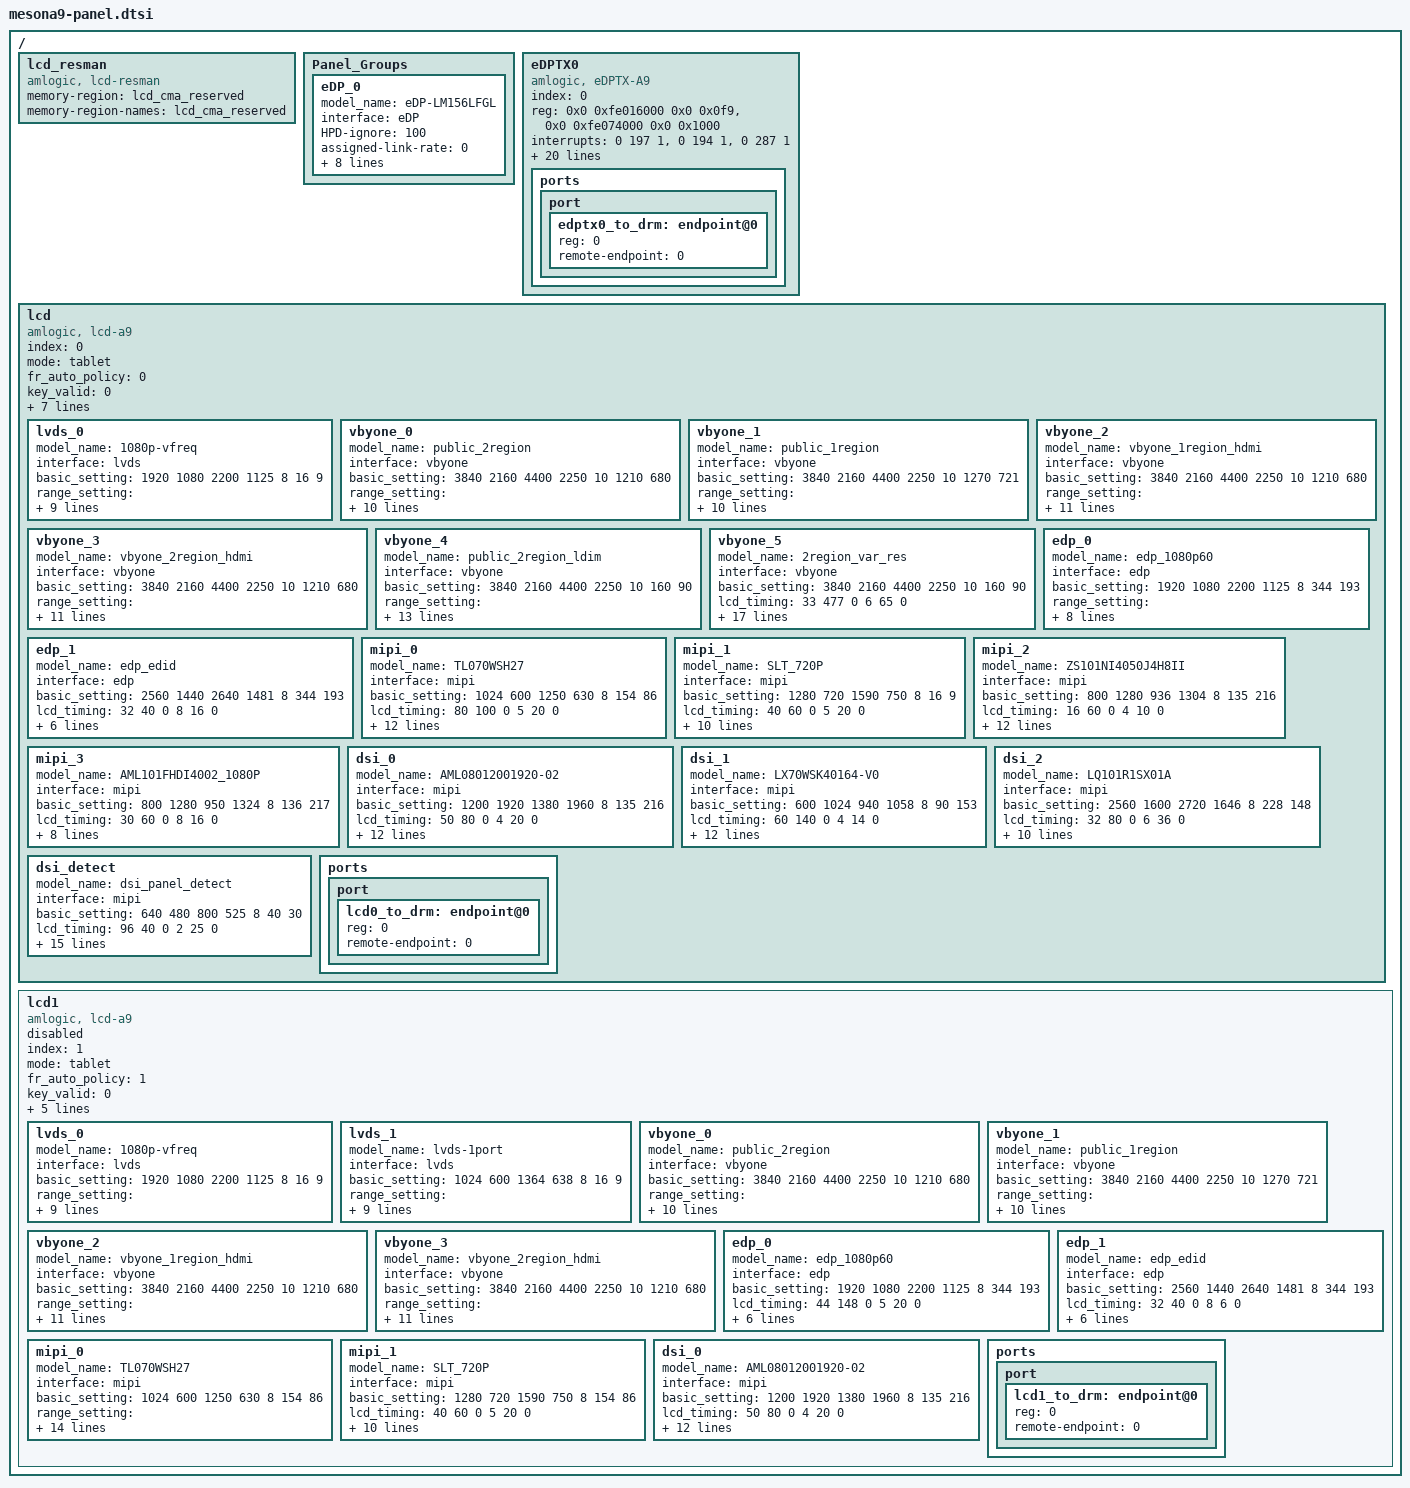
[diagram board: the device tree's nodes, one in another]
// SPDX-License-Identifier: (GPL-2.0+ OR MIT)
/*
 * Copyright (c) 2019 Amlogic, Inc. All rights reserved.
 */

/ {
	lcd_resman {
		compatible = "amlogic, lcd-resman";
		status = "okay";
		memory-region = <&lcd_cma_reserved>;
		memory-region-names = "lcd_cma_reserved";
	};

	Panel_Groups {
		eDP_0 {
			model_name = "eDP-LM156LFGL";
			interface = "eDP"; /*lcd_interface(lvds, vbyone)*/
			HPD-ignore = <100>;

			assigned-link-rate = <0>;
			assigned-lane-count = <0>;
			assigned-port-count = <0>;
			assigned-vmode = <0>;
			assigned-disable-PSR = <0>;
			use-aux-backlight = <0>;

			assigned-preset-timing = <0>;

			///*h(period active sync bp pol) v(period active sync bp pol) dft fr*/
			//timing-0 = <2180 1920 32 180 0 1282 1080 5 194 0 24 48>;
			//timing-0-fr = <48 50 60>; /* timing with fixed fr */
			//timing-0-range-limit = <
			//	2132 2650  /*h_period_min,max*/
			//	1120 1480  /*v_period_min,max*/
			//	120000000 160000000>; /*pclk_min,max*/
			//timing-0-range = <48 60>; /* timing with fixed fr */

			phy_attr=<1 2 0>; /*Fast-LT vswing, Pre-Em, Post-Cur*/
			bl-wrapper-id = <0xff000000>;
		};
	};

	eDPTX0:eDPTX0 {
		compatible = "amlogic, eDPTX-A9";
		status = "okay";
		index = <0>;

		reg = <0x0 0xfe016000 0x0 0x0f9>,    /* combo dphy */
		      <0x0 0xfe074000 0x0 0x1000>;  /* edp_a host */
		//power-domains = <&pwrdm PDID_T7_EDP0>;
		interrupts = <0 197 1>,<0 194 1>,<0 287 1>;
		interrupt-names = "vsync","vsync2","eDPTX-HPD";
		pinctrl-names = "edptx_hpd","edptx_hpd_off";
		pinctrl-0 = <&edptx_0_hpd_pins>;
		pinctrl-1 = <&edptx_0_hpd_off_pins>;
		device_name = "amlogic-eDPTX0";

		HPD-ignore = <100>;

		//edptx_vcc-gpio      = <&gpio GPIOY_0 GPIO_ACTIVE_HIGH>;
		//edptx_vcc-gpio-name = "GPIOY_0";
		//edptx_vcc_on_dir = <1>;
		//edptx_vcc-off_dir = <0>;

		edptx_bl_en-gpio      = <&gpio GPIOY_0 GPIO_ACTIVE_HIGH>;
		edptx_bl_en-gpio-name = "GPIOY_0";
		edptx_bl_en_on_dir = <1>;
		edptx_bl_en-off_dir = <0>;
		edptx_bl_pwm-gpio      = <&gpio GPIOY_1 GPIO_ACTIVE_HIGH>;
		edptx_bl_pwm-gpio-name = "GPIOY_1";
		edptx_bl_pwm_on_dir = <1>;
		edptx_bl_pwm-off_dir = <0>;

		edptx_bist-gpio      = <&gpio GPIOY_3 GPIO_ACTIVE_HIGH>;
		edptx_bist-gpio-name = "GPIOY_3";
		edptx_bist_on_dir = <1>;
		edptx_bist-off_dir = <0>;

		//edptx_hpd-gpio      = <&gpio GPIOY_7 GPIO_ACTIVE_HIGH>;
		//edptx_hpd-gpio-name = "GPIOY_7";

		drive-strength-lut =
			<0x3 0x3 0x0>,<0x3 0x7 0x0>,<0x3 0xb 0x0>,<0x3 0xf 0x0>,
			<0x7 0x3 0x0>,<0x7 0x8 0x0>,<0x8 0xc 0x0>,
			<0xa 0x4 0x0>,<0xa 0x8 0x0>,
			<0xf 0x5 0x0>;

		ports {
			port {
				#address-cells = <1>;
				#size-cells = <0>;
				edptx0_to_drm: endpoint@0 {
					reg = <0>;
					remote-endpoint = <0>;
				};
			};
		};
	};

	lcd:lcd {
		compatible = "amlogic, lcd-a9";
		status = "okay";
		index = <0>;
		mode = "tablet";
		fr_auto_policy = <0>; /* 0=disable, 1=60/50hz, 2=60/50/48hz */
		key_valid = <0>;
		reg = <0x0 0xfe01e000 0x0 0x400   /* mipi_dsi0-A host */
			0x0 0xfe01c000 0x0 0x200   /* mipi_dsi0-A phy */
			0x0 0xfe072000 0x0 0x400   /* mipi_dsi0-B host */
			0x0 0xfe018000 0x0 0x200   /* mipi_dsi0-B phy */
			0x0 0xfe016000 0x0 0x3e4
			0x0 0xfe004000 0x0 0x070>;  /* vx1_lvds_ctrl */
		interrupts = <0 197 1>, <0 194 1>, <0 208 1>;
		interrupt-names = "vsync","vsync2","vbyone";
		pinctrl-names = "vbyone","vbyone_off";
		pinctrl-0 = <&lcd_vbyone_a_pins>;
		pinctrl-1 = <&lcd_vbyone_a_off_pins>;

		config_check_glb = <1>;
		display_timing_req_min = <1  /*alert_level: 0:disable, 1:warning, 2:fatal error*/
			45   /*hsw+hbp*/
			0    /*hfp, 0 for no need*/
			20   /*vsw+vbp*/
			15>; /*vfp*/
		lvds_0{
			model_name = "1080p-vfreq";
			interface = "lvds"; /*lcd_interface(lvds, vbyone)*/
			basic_setting = <
				1920 1080 /*h_active, v_active*/
				2200 1125 /*h_period, v_period*/
				8      /*lcd_bits */
				16 9>; /*screen_widht, screen_height*/
			range_setting = <
				2132 2650  /*h_period_min,max*/
				1120 1480  /*v_period_min,max*/
				120000000 160000000>; /*pclk_min,max*/
			lcd_timing = <
				44 148 0  /*hs_width, hs_bp, hs_pol*/
				5  20 0>; /*vs_width, vs_bp, vs_pol*/
			clk_attr = <
				2 /*fr_adj_type: 0=clk, 1=htotal, 2=vtotal, 3=auto, 4=hdmi */
				0 /*clk_ss: [0:7]:level, [8:11]:freq, [12:15]: mode*/
				1 /*clk_auto_generate*/
				0>; /*pixel_clk(unit in Hz)*/
			lvds_attr = <
				1  /*lvds_repack*/
				1  /*dual_port*/
				0  /*pn_swap*/
				0  /*port_swap*/
				0>; /*lane_reverse*/
			phy_attr=<0x3 0>; /*vswing_level, preem_level*/
			hw_filter=<0 0>;  /* filter_time, filter_cnt*/

			/* power step: type, index, value, delay(ms) */
			power_on_step = <
				2 0 0 0   /*signal enable*/
				0xff 0 0 0>; /*ending*/
			power_off_step = <
				2 0 0 10  /*signal disable*/
				0xff 0 0 0>; /*ending*/
			backlight_index = <0xff>;
		};
		vbyone_0{
			model_name = "public_2region";
			interface = "vbyone"; /*lcd_interface(lvds, vbyone)*/
			basic_setting = <
				3840 2160 /*h_active, v_active*/
				4400 2250 /*h_period, v_period*/
				10     /*lcd_bits */
				1210 680>; /*screen_widht, screen_height*/
			range_setting = <
				4370 4800 /*h_period_min, max*/
				2246 2760 /*v_period_min, max*/
				480000000 624000000>; /*pclk_min, max*/
			lcd_timing = <
				33 477 0  /*hs_width, hs_bp, hs_pol*/
				6  65 0>; /*vs_width, vs_bp, vs_pol*/
			clk_attr = <
				2 /*fr_adj_type: 0=clk, 1=htotal, 2=vtotal, 3=auto, 4=hdmi */
				0 /*clk_ss: [0:7]:level, [8:11]:freq, [12:15]: mode*/
				1 /*clk_auto_generate*/
				0>; /*pixel_clk(unit in Hz)*/
			vbyone_attr = <
				8 /*lane_count*/
				2 /*region_num*/
				4 /*byte_mode*/
				4>; /*color_fmt*/
			vbyone_intr_enable = <
				1 /*vbyone_intr_enable */
				3>; /*vbyone_vsync_intr_enable*/
			phy_attr=<0x8 0xf>; /* vswing_level, preem_level */
			hw_filter=<0 0>;  /* filter_time, filter_cnt*/

			/* power step: type, index, value, delay(ms) */
			power_on_step = <
				0 0 1 200  /*panel power on*/
				2 0 0 10  /*signal enable*/
				0xff 0 0 0>; /*ending*/
			power_off_step = <
				2 0 0 10 /*signal disable*/
				0 0 0 500 /*panel power off*/
				0xff 0 0 0>; /*ending*/
			backlight_index = <0>;
		};
		vbyone_1{
			model_name = "public_1region";
			interface = "vbyone"; /*lcd_interface(lvds, vbyone)*/
			basic_setting = <
				3840 2160 /*h_active, v_active*/
				4400 2250 /*h_period, v_period*/
				10     /*lcd_bits*/
				1270 721>; /*screen_widht, screen_height*/
			range_setting = <
				4370 4800 /*h_period_min, max*/
				2246 2790 /*v_period_min, max*/
				552000000 632000000>; /*pclk_min,max*/
			lcd_timing = <
				33 477 0   /*hs_width, hs_bp, hs_pol*/
				6  65  0>; /*vs_width, vs_bp, vs_pol*/
			clk_attr = <
				2 /*fr_adj_type: 0=clk, 1=htotal, 2=vtotal, 3=auto, 4=hdmi */
				0 /*clk_ss: [0:7]:level, [8:11]:freq, [12:15]: mode*/
				1 /*clk_auto_generate*/
				0>; /*pixel_clk(unit in Hz)*/
			vbyone_attr = <
				8 /*lane_count*/
				1 /*region_num*/
				4 /*byte_mode*/
				4>; /*color_fmt*/
			vbyone_intr_enable = <
				1   /*vbyone_intr_enable*/
				3>; /*vbyone_vsync_intr_enable*/
			phy_attr=<0x8 0xf>; /* vswing_level, preem_level */
			hw_filter=<0 0>;  /* filter_time, filter_cnt*/

			/* power step: type, index, value, delay(ms) */
			power_on_step = <
				0 0 1 200  /*panel power on*/
				2 0 0 10 /*signal enable*/
				0xff 0 0 0>; /*ending*/
			power_off_step = <
				2 0 0 10  /*signal disable*/
				0 0 0 500 /*panel power off*/
				0xff 0 0 0>; /*ending*/
			backlight_index = <0>;
		};
		vbyone_2{
			model_name = "vbyone_1region_hdmi";
			interface = "vbyone"; /*lcd_interface(lvds, vbyone)*/
			basic_setting = <
				3840 2160 /*h_active, v_active*/
				4400 2250 /*h_period, v_period*/
				10     /*lcd_bits */
				1210 680>; /*screen_widht, screen_height*/
			range_setting = <
				4370 4800 /*h_period_min, max*/
				2246 2760 /*v_period_min, max*/
				480000000 624000000>; /*pclk_min, max*/
			lcd_timing = <
				33 477 0  /*hs_width, hs_bp, hs_pol*/
				6  65 0>; /*vs_width, vs_bp, vs_pol*/
			clk_attr = <
				4 /*fr_adj_type: 0=clk, 1=htotal, 2=vtotal, 3=auto, 4=hdmi */
				0 /*clk_ss: [0:7]:level, [8:11]:freq, [12:15]: mode*/
				1 /*clk_auto_generate*/
				0>; /*pixel_clk(unit in Hz)*/
			vbyone_attr = <
				8 /*lane_count*/
				1 /*region_num*/
				4 /*byte_mode*/
				4>; /*color_fmt*/
			vbyone_intr_enable = <
				1 /*vbyone_intr_enable */
				3>; /*vbyone_vsync_intr_enable*/
			phy_attr=<0x8 0xf>; /* vswing_level, preem_level */
			hw_filter=<0 0>;  /* filter_time, filter_cnt*/
			//vlock_attr: <vlock_en vlock_mode pll_m limit line_limit>
			vlock_attr = <0 4 0 3>;
			/* power step: type, index, value, delay(ms) */
			power_on_step = <
				0 0 1 20  /*panel power on*/
				2 0 0 0  /*signal enable*/
				0xff 0 0 0>; /*ending*/
			power_off_step = <
				2 0 0 20 /*signal disable*/
				0 0 0 100 /*panel power off*/
				0xff 0 0 0>; /*ending*/
			backlight_index = <0xff>;
		};
		vbyone_3{
			model_name = "vbyone_2region_hdmi";
			interface = "vbyone"; /*lcd_interface(lvds, vbyone)*/
			basic_setting = <
				3840 2160 /*h_active, v_active*/
				4400 2250 /*h_period, v_period*/
				10     /*lcd_bits */
				1210 680>; /*screen_widht, screen_height*/
			range_setting = <
				4370 4800 /*h_period_min, max*/
				2246 2760 /*v_period_min, max*/
				480000000 624000000>; /*pclk_min, max*/
			lcd_timing = <
				33 477 0  /*hs_width, hs_bp, hs_pol*/
				6  65 0>; /*vs_width, vs_bp, vs_pol*/
			clk_attr = <
				4 /*fr_adj_type: 0=clk, 1=htotal, 2=vtotal, 3=auto, 4=hdmi */
				0 /*clk_ss: [0:7]:level, [8:11]:freq, [12:15]: mode*/
				1 /*clk_auto_generate*/
				0>; /*pixel_clk(unit in Hz)*/
			vbyone_attr = <
				8 /*lane_count*/
				2 /*region_num*/
				4 /*byte_mode*/
				4>; /*color_fmt*/
			vbyone_intr_enable = <
				1 /*vbyone_intr_enable */
				3>; /*vbyone_vsync_intr_enable*/
			phy_attr=<0x8 0xf>; /* vswing_level, preem_level */
			hw_filter=<0 0>;  /* filter_time, filter_cnt*/
			//vlock_attr: <vlock_en vlock_mode pll_m limit line_limit>
			vlock_attr = <0 4 0 3>;
			/* power step: type, index, value, delay(ms) */
			power_on_step = <
				0 0 1 20  /*panel power on*/
				2 0 0 0  /*signal enable*/
				0xff 0 0 0>; /*ending*/
			power_off_step = <
				2 0 0 20 /*signal disable*/
				0 0 0 100 /*panel power off*/
				0xff 0 0 0>; /*ending*/
			backlight_index = <0xff>;
		};
		vbyone_4{/*for localdimming*/
			model_name = "public_2region_ldim";
			interface = "vbyone"; /*lcd_interface(lvds, vbyone)*/
			basic_setting = <
				3840 2160 /*h_active, v_active*/
				4400 2250 /*h_period, v_period*/
				10     /*lcd_bits */
				160 90>; /*screen_widht, screen_height*/
			range_setting = <
				4370 4800 /*h_period_min, max*/
				2246 2760 /*v_period_min, max*/
				480000000 624000000>; /*pclk_min, max*/
			lcd_timing = <
				33 477 0  /*hs_width, hs_bp, hs_pol*/
				6  65 0>; /*vs_width, vs_bp, vs_pol*/
			clk_attr = <
				2 /*fr_adj_type: 0=clk, 1=htotal, 2=vtotal, 3=auto, 4=hdmi */
				0 /*clk_ss: [0:7]:level, [8:11]:freq, [12:15]: mode*/
				1 /*clk_auto_generate*/
				0>; /*pixel_clk(unit in Hz)*/
			vbyone_attr = <
				8 /*lane_count*/
				2 /*region_num*/
				4 /*byte_mode*/
				4>; /*color_fmt*/
			vbyone_intr_enable = <
				1 /*vbyone_intr_enable */
				3>; /*vbyone_vsync_intr_enable*/
			hw_filter=<0 0>;  /* filter_time, filter_cnt*/
			phy_attr=<0x8 0xf>; /* vswing_level, preem_level */

			phy_adv_attr=<0x100a 0 0x2f 0 0x2>; /*flag, vswing, vcm, bias, odt*/
			phy_lane_ctrl = </*bit[31:16]amp, bit[15:0]preem*/
				0x000000e7 0x000000e7 0x000000e7 0x000000e7
				0x000000e7 0x000000e7 0x000000e7 0x000000e7>;

			/* power step: type, index, value, delay(ms) */
			power_on_step = <
				0 2 1 200  /*panel power on*/
				2 0 0 10  /*signal enable*/
				0xff 0 0 0>; /*ending*/
			power_off_step = <
				2 0 0 10 /*signal disable*/
				0 2 0 500 /*panel power off*/
				0xff 0 0 0>; /*ending*/
			backlight_index = <3>;
		};

		vbyone_5{
			model_name = "2region_var_res";
			interface = "vbyone"; /*lcd_interface(lvds, vbyone)*/
			basic_setting = <
				3840 2160 /*h_active, v_active*/
				4400 2250 /*h_period, v_period*/
				10     /*lcd_bits */
				160 90>; /*screen_widht, screen_height*/
			lcd_timing = <
				33 477 0  /*hs_width, hs_bp, hs_pol*/
				6  65 0>; /*vs_width, vs_bp, vs_pol*/
			clk_attr = <
				0xff /*fr_adj_type: 0=clk, 1=htotal, 2=vtotal, 3=auto, 4=hdmi */
				0 /*clk_ss: [0:7]:level, [8:11]:freq, [12:15]: mode*/
				1 /*clk_auto_generate*/
				594000000>; /*pixel_clk(unit in Hz)*/
			vbyone_attr = <
				8 /*lane_count*/
				2 /*region_num*/
				4 /*byte_mode*/
				4>; /*color_fmt*/
			vbyone_intr_enable = <
				1 /*vbyone_intr_enable */
				3>; /*vbyone_vsync_intr_enable*/
			cus_ctrl_0_attr = <0x02 0x03>;
			extend_tmg_0 = <2720 2560 60 40  0 1481 1440 5 20 0 8 344 193 241500000>;
			extend_tmg_1 = <2200 1920 44 148 0 1125 1080 4  5 0 8 344 193 148500000>;
			extend_tmg_2 = <1650 1280 40 220 0 750  720  5  5 0 8 344 193  74250000>;
			extend_tmg_3 = <800  640  96 40  0 525  480  2 25 0 8 344 193  25175000>;

			phy_attr=<0x8 0xf>; /* vswing_level, preem_level */
			hw_filter=<0 0>;  /* filter_time, filter_cnt*/

			/* power step: type, index, value, delay(ms) */
			power_on_step = <
				0 2 1 200  /*panel power on*/
				2 0 0 10  /*signal enable*/
				0xff 0 0 0>; /*ending*/
			power_off_step = <
				2 0 0 10 /*signal disable*/
				0 2 0 100 /*panel power off*/
				0xff 0 0 0>; /*ending*/
			backlight_index = <0xff>;
		};

		edp_0{
			model_name = "edp_1080p60";
			interface = "edp"; /*lcd_interface(lvds, vbyone)*/
			basic_setting = <
				1920 1080 /*h_active, v_active*/
				2200 1125 /*h_period, v_period*/
				8      /*lcd_bits*/
				344 193>; /*screen_widht, screen_height*/
			range_setting = <
				2132 2720 /*h_period min, max*/
				1120 1380 /*v_period min, max*/
				133940000 156000000>; /*pclk_min, max*/
			lcd_timing = <
				44 148 0   /*hs_width, hs_bp, hs_pol*/
				5  20  0>; /*vs_width, vs_bp, vs_pol*/
			clk_attr = <
				0 /*fr_adj_type: 0=clk, 1=htotal, 2=vtotal, 3=auto, 4=hdmi */
				0 /*clk_ss_level */
				1 /*clk_auto_generate*/
				0>; /*pixel_clk(unit in Hz)*/
			edp_attr = <
				2 /*max_lane_count: 0:auto, 1, 2, 4*/
				0xa /*max_link_rate: 0:auto, 0x6:1.62G, 0xa:2.7G*/
				0 /*training_mode: 0:auto, 1:fast, 2:full*/
				0 /*edid_en, auto timing by edid*/
				0 /*reserved */
				0 /*reserved */
				0 /*reserved */
				0 /*reserved */
				0>; /*reserved*/
			phy_attr=<0x5 1>; /*vswing_level, preem_level*/

			/* power step: type, index, value, delay(ms) */
			power_on_step = <
				0 0 1 50  /*panel power on*/
				2 0 0 0   /*signal enable*/
				0xff 0 0 0>; /*ending*/
			power_off_step = <
				2 0 0 10  /*signal disable*/
				0 0 0 200  /*panel power on*/
				0xff 0 0 0>; /*ending*/
			backlight_index = <0x0>;
		};
		edp_1{
			model_name = "edp_edid";
			interface = "edp"; /*lcd_interface(lvds, vbyone)*/
			basic_setting = <
				2560 1440 /*h_active, v_active*/
				2640 1481 /*h_period, v_period*/
				8      /*lcd_bits*/
				344 193>; /*screen_widht, screen_height*/
			lcd_timing = <
				32 40 0   /*hs_width, hs_bp, hs_pol*/
				8  16  0>; /*vs_width, vs_bp, vs_pol*/
			clk_attr = <
				2 /*fr_adj_type: 0=clk, 1=htotal, 2=vtotal, 3=auto, 4=hdmi */
				0 /*clk_ss_level */
				1 /*clk_auto_generate*/
				235000000>; /*pixel_clk(unit in Hz)*/
			edp_attr = <
				0 /*max_lane_count: 0:auto, 1, 2, 4*/
				0 /*max_link_rate: 0:auto, 0x6:1.62G, 0xa:2.7G*/
				0 /*training_mode: 0:auto, 1:fast, 2:full*/
				1 /*edid_en, auto timing by edid*/
				0 /*reserved */
				0 /*reserved */
				0 /*reserved */
				0 /*reserved */
				0>; /*reserved*/
			phy_attr=<0x5 1>; /*vswing_level, preem_level*/

			/* power step: type, index, value, delay(ms) */
			power_on_step = <
				0 0 1 50  /*panel power on*/
				2 0 0 0   /*signal enable*/
				0xff 0 0 0>; /*ending*/
			power_off_step = <
				2 0 0 10  /*signal disable*/
				0 0 0 200  /*panel power on*/
				0xff 0 0 0>; /*ending*/
			backlight_index = <0x0>;
		};

		mipi_0{
			model_name = "TL070WSH27";
			interface = "mipi";
			/*h_active, v_active, h_period, v_period, color_bit, width, height*/
			basic_setting = <1024 600 1250 630 8 154 86>;
			/*hs_width, hs_bp, hs_pol, vs_width, vs_bp, vs_pol*/
			lcd_timing = <80 100 0 5 20 0>;
			/* fr_adj_type(0=clk, 1=htotal, 2=vtotal), clk_ss_level, 1, pixel_clk */
			clk_attr = <0 0 1 47250000>;
			/* <lane, bit_rate, /, mode_init(0=video,1=cmd), mode_disp(0=video,1=cmd)*/
			/* video_mode(0=sync_pulse,1=sync_event,2=burst), clk_hs, />*/
			mipi_attr = <4 300 0 1 0 2 1 0>;
			/* dsi_init: data_type, num, data... */
			dsi_init_on = <
				0x05 1 0x11
				0xfd 1 20 /*delay(ms)*/
				0x05 1 0x29
				0xfd 1 20 /*delay(ms)*/
				0xff 0>; /*ending*/
			dsi_init_off = <0x05 1 0x28
				0xfd 1 10 /*delay(ms)*/
				0x05 1 0x10
				0xfd 1 10 /*delay(ms)*/
				0xff 0>; /*ending*/
			extern_init = <0xff>; /*0xff for invalid*/

			/* power step: type, index, value, delay(ms) */
			power_on_step = <
				0 0 1 100
				0 1 0 10
				0 1 1 20
				2 0 0 0
				0xff 0 0 0>; /*ending*/
			power_off_step = <
				2 0 0 50
				0 1 0 10
				0 0 0 100
				0xff 0 0 0>; /*ending*/
			backlight_index = <0x1>;
		};
		mipi_1{
			model_name = "SLT_720P";
			interface = "mipi";
			/*h_active, v_active, h_period, v_period, color_bit, width, height*/
			basic_setting = <1280 720 1590 750 8 16 9>;
			/*hs_width, hs_bp, hs_pol, vs_width, vs_bp, vs_pol*/
			lcd_timing = <40 60 0 5 20 0>;
			/* fr_adj_type(0=clk, 1=htotal, 2=vtotal), clk_ss_level, 1, pixel_clk */
			clk_attr = <0 0 1 74250000>;
			/* <lane, bit_rate, /, mode_init(0=video,1=cmd), mode_disp(0=video,1=cmd)*/
			/* video_mode(0=sync_pulse,1=sync_event,2=burst), clk_hs, />*/
			mipi_attr = <4 550 0 1 0 0 1 0>;
			/* dsi_init: data_type, num, data... */
			dsi_init_on = <
				0x05 1 0x11
				0xff 200
				0x05 1 0x29
				0xff 20
				0xff 0xff>; /* ending flag */
			dsi_init_off = <
				0x05 1 0x28
				0xff 10
				0x05 1 0x10
				0xff 10
				0xff 0xff>; /* ending flag */
			/* extern_init: 0xff for invalid */
			extern_init = <0xff>;
			/* power step: type,index,value,delay(ms) */
			power_on_step = <
				3 7 0 100
				2 0 0 0
				0xff 0 0 0>;
			power_off_step = <
				2 0 0 0
				0xff 0 0 0>;
			backlight_index = <0xff>;
		};

		mipi_2{
			model_name = "ZS101NI4050J4H8II";
			interface = "mipi";
			/*h_active, v_active, h_period, v_period, color_bit, width, height*/
			basic_setting = <800 1280 936 1304 8 135 216>;
			/*hs_width, hs_bp, hs_pol, vs_width, vs_bp, vs_pol*/
			lcd_timing = <16 60 0 4 10 0>;
			/* fr_adj_type(0=clk, 1=htotal, 2=vtotal), clk_ss_level, 1, pixel_clk */
			clk_attr = <2 0 1 73232640>;
			/* <lane, bit_rate, /, mode_init(0=video,1=cmd), mode_disp(0=video,1=cmd)*/
			/* video_mode(0=sync_pulse,1=sync_event,2=burst), clk_hs, />*/
			mipi_attr = <4 1000 0 1 0 2 1 0>;

			/* dsi_init: data_type, num, data... */
			dsi_init_on = <
				0xfd 1 10
				0xf0 3 1 1 50
				0xf0 3 1 0 50
				0xf0 3 1 1 50
				0x39 4 0xFF 0x98 0x81 0x03
				0x15 2 0x01 0x00 0x15 2 0x02 0x00 0x15 2 0x03 0x53 0x15 2 0x04 0x53
				0x15 2 0x05 0x13 0x15 2 0x06 0x04 0x15 2 0x07 0x02 0x15 2 0x08 0x02
				0x15 2 0x09 0x00 0x15 2 0x0a 0x00 0x15 2 0x0b 0x00 0x15 2 0x0c 0x00
				0x15 2 0x0d 0x00 0x15 2 0x0e 0x00 0x15 2 0x0f 0x00 0x15 2 0x10 0x00
				0x15 2 0x11 0x00 0x15 2 0x12 0x00 0x15 2 0x13 0x00 0x15 2 0x14 0x00
				0x15 2 0x15 0x05 0x15 2 0x16 0x05 0x15 2 0x17 0x03 0x15 2 0x18 0x03
				0x15 2 0x19 0x00 0x15 2 0x1a 0x00 0x15 2 0x1b 0x00 0x15 2 0x1c 0x00
				0x15 2 0x1d 0x00 0x15 2 0x1e 0xc0 0x15 2 0x1f 0x00 0x15 2 0x20 0x02
				0x15 2 0x21 0x09 0x15 2 0x22 0x00 0x15 2 0x23 0x00 0x15 2 0x24 0x00
				0x15 2 0x25 0x00 0x15 2 0x26 0x00 0x15 2 0x27 0x00 0x15 2 0x28 0x55
				0x15 2 0x29 0x03 0x15 2 0x2a 0x00 0x15 2 0x2b 0x00 0x15 2 0x2c 0x00
				0x15 2 0x2d 0x00 0x15 2 0x2e 0x00 0x15 2 0x2f 0x00 0x15 2 0x30 0x00
				0x15 2 0x31 0x00 0x15 2 0x32 0x00 0x15 2 0x33 0x00 0x15 2 0x34 0x00
				0x15 2 0x35 0x00 0x15 2 0x36 0x00 0x15 2 0x37 0x00 0x15 2 0x38 0x3C
				0x15 2 0x39 0x00 0x15 2 0x3a 0x00 0x15 2 0x3b 0x00 0x15 2 0x3c 0x00
				0x15 2 0x3d 0x00 0x15 2 0x3e 0x00 0x15 2 0x3f 0x00 0x15 2 0x40 0x00
				0x15 2 0x41 0x00 0x15 2 0x42 0x00 0x15 2 0x43 0x00 0x15 2 0x44 0x00
				0x15 2 0x50 0x01 0x15 2 0x51 0x23 0x15 2 0x52 0x45 0x15 2 0x53 0x67
				0x15 2 0x54 0x89 0x15 2 0x55 0xab 0x15 2 0x56 0x01 0x15 2 0x57 0x23
				0x15 2 0x58 0x45 0x15 2 0x59 0x67 0x15 2 0x5a 0x89 0x15 2 0x5b 0xab
				0x15 2 0x5c 0xcd 0x15 2 0x5d 0xef 0x15 2 0x5e 0x01 0x15 2 0x5f 0x0A
				0x15 2 0x60 0x02 0x15 2 0x61 0x02 0x15 2 0x62 0x08 0x15 2 0x63 0x15
				0x15 2 0x64 0x14 0x15 2 0x65 0x02 0x15 2 0x66 0x11 0x15 2 0x67 0x10
				0x15 2 0x68 0x02 0x15 2 0x69 0x0F 0x15 2 0x6a 0x0E 0x15 2 0x6b 0x02
				0x15 2 0x6c 0x0D 0x15 2 0x6d 0x0C 0x15 2 0x6e 0x06 0x15 2 0x6f 0x02
				0x15 2 0x70 0x02 0x15 2 0x71 0x02 0x15 2 0x72 0x02 0x15 2 0x73 0x02
				0x15 2 0x74 0x02 0x15 2 0x75 0x0A 0x15 2 0x76 0x02 0x15 2 0x77 0x02
				0x15 2 0x78 0x06 0x15 2 0x79 0x15 0x15 2 0x7a 0x14 0x15 2 0x7b 0x02
				0x15 2 0x7c 0x10 0x15 2 0x7d 0x11 0x15 2 0x7e 0x02 0x15 2 0x7f 0x0C
				0x15 2 0x80 0x0D 0x15 2 0x81 0x02 0x15 2 0x82 0x0E 0x15 2 0x83 0x0F
				0x15 2 0x84 0x08 0x15 2 0x85 0x02 0x15 2 0x86 0x02 0x15 2 0x87 0x02
				0x15 2 0x88 0x02 0x15 2 0x89 0x02 0x15 2 0x8A 0x02
				0x39 4 0xFF 0x98 0x81 0x04
				0x15 2 0x3B 0xC0 0x15 2 0x6C 0x15 0x15 2 0x6E 0x30 0x15 2 0x6F 0x33
				0x15 2 0x8D 0x1F 0x15 2 0x3A 0x24 0x15 2 0x35 0x1F 0x15 2 0x87 0xBA
				0x15 2 0x26 0x76 0x15 2 0xB2 0xD1 0x15 2 0xB5 0x07 0x15 2 0x88 0x0B
				0x15 2 0x21 0x30
				0x39 4 0xFF 0x98 0x81 0x01
				0x15 2 0x22 0x0A 0x15 2 0x31 0x09 0x15 2 0x40 0x33 0x15 2 0x42 0x44
				0x15 2 0x53 0x2E 0x15 2 0x55 0x88 0x15 2 0x50 0x95 0x15 2 0x51 0x95
				0x15 2 0x60 0x43 0x15 2 0x2E 0xC8 0x15 2 0xA0 0x0F 0x15 2 0xA1 0x1D
				0x15 2 0xA2 0x2A 0x15 2 0xA3 0x14 0x15 2 0xA4 0x16 0x15 2 0xA5 0x29
				0x15 2 0xA6 0x1D 0x15 2 0xA7 0x1E 0x15 2 0xA8 0x83 0x15 2 0xA9 0x1E
				0x15 2 0xAA 0x2B 0x15 2 0xAB 0x6F 0x15 2 0xAC 0x18 0x15 2 0xAD 0x17
				0x15 2 0xAE 0x4C 0x15 2 0xAF 0x22 0x15 2 0xB0 0x27 0x15 2 0xB1 0x4D
				0x15 2 0xB2 0x5C 0x15 2 0xB3 0x2B 0x15 2 0xC0 0x0F 0x15 2 0xC1 0x1D
				0x15 2 0xC2 0x2A 0x15 2 0xC3 0x14 0x15 2 0xC4 0x16 0x15 2 0xC5 0x29
				0x15 2 0xC6 0x1D 0x15 2 0xC7 0x1E 0x15 2 0xC8 0x83 0x15 2 0xC9 0x1E
				0x15 2 0xCA 0x2B 0x15 2 0xCB 0x6F 0x15 2 0xCC 0x18 0x15 2 0xCD 0x17
				0x15 2 0xCE 0x4C 0x15 2 0xCF 0x22 0x15 2 0xD0 0x27 0x15 2 0xD1 0x4D
				0x15 2 0xD2 0x5C 0x15 2 0xD3 0x2B
				0x39 4 0xFF 0x98 0x81 0x00
				0x15 2 0x35 0x00
				0x05 1 0x11
				0xfd 1 120
				0x05 1 0x29
				0xfd 1 20
				0xff 0>; /*ending*/
			dsi_init_off = <
				0x05 1 0x28
				0xff 10
				0x05 1 0x10
				0xff 0xff>; /*ending*/
			extern_init = <0xff>; /*0xff for invalid*/

			/* power step: type, index, value, delay(ms) */
			power_on_step = <
				0 0 1 10 /*vcc en*/
				0 1 1 1 /*rst high*/
				0 3 1 30 /*3v3 high*/
				0 1 0 10 /*rst low*/
				0 1 1 20 /*rst high*/
				2 0 0 0
				0xff 0 0 0>; /*ending*/
			power_off_step = <
				2 0 0 10
				0 0 0 1
				0 1 0 1 /*rst low*/
				0 3 0 1 /*3v3 low*/
				0xff 0 0 0>; /*ending*/
			backlight_index = <0>;
		};
		mipi_3{
			model_name = "AML101FHDI4002_1080P";
			interface = "mipi";
			basic_setting = <800 1280/*h_active, v_active*/
					950 1324 /*h_period, v_period*/
					8 /*lcd_bits*/
					136 217>; /*screen_widht, screen_height*/
			lcd_timing = <30 60 0 /*hs_width,hs_bp,hs_pol*/
					8 16 0>; /*vs_width,vs_bp,vs_pol*/
			clk_attr = <0 /*fr_adj_type(0=clock,1=htotal,2=vtotal)*/
					0 /*clk_ss: [0:7]:level, [8:11]:freq, [12:15]: mode*/
					1 /*clk_auto_generate*/
					67800000>; /*pixel_clk(unit in Hz)*/
			mipi_attr = <4 /*lane_num*/
					480 /*bit_rate_max(MHz)*/
					0 /*unused*/
					1 /*operation_mode_init(0=video, 1=command)*/
					0 /*operation_mode_display(0=video, 1=command)*/
					2 /*
					   *video_mode_type
					   *(0=sync_pulse,1=sync_event,2=burst)
					   */
					1 /*clk_always_hs(0=disable,1=enable)*/
					0>; /*unused*/
			/* dsi_init: data_type, num, data... */
			dsi_init_on = <0xFF 0>;	/*ending*/
			init_off = <0xff 0>;	/*ending*/
			/* extern_init: 0xff for invalid */
			extern_init = <0>;
					/* power step: type,index,value,delay(ms) */
			power_on_step = <
				2 0 0 100
				0xff 0 0 0>;
			power_off_step = <
				2 0 0 0
				0xff 0 0 0>;
			backlight_index = <0xff>;
		};

		dsi_0{
			model_name = "AML08012001920-02";
			interface = "mipi";
			/*h_active, v_active, h_period, v_period, color_bit, width, height*/
			basic_setting = <1200 1920 1380 1960 8 135 216>;
			/*hs_width, hs_bp, hs_pol, vs_width, vs_bp, vs_pol*/
			lcd_timing = <50 80 0 4 20 0>;
			clk_attr = <2 0 1 164000000>;
			/* <lane, bit_rate, /, mode_init(0=video,1=cmd), mode_disp(0=video,1=cmd)*/
			/* video_mode(0=sync_pulse,1=sync_event,2=burst), clk_hs, />*/
			mipi_attr = <4 1020 0 1 0 2 1 0>;
			/* dsi_init: data_type, num, data... */
			dsi_init_on = <
				0xfd 1 150
				0x05 1 0x10
				0xfd 1 10
				0x15 2 0xB0 0x05 0x15 2 0xB3 0x52 0x15 2 0xB0 0x01 0x15 2 0xC8 0x00
				0x15 2 0xC9 0x00 0x15 2 0xCC 0x26 0x15 2 0xCD 0x26 0x15 2 0xDC 0x00
				0x15 2 0xDD 0x00 0x15 2 0xE0 0x26 0x15 2 0xE1 0x26 0x15 2 0xB0 0x03
				0x15 2 0xC3 0x2A 0x15 2 0xE7 0x2A 0x15 2 0xC5 0x2A 0x15 2 0xDE 0x2A
				0x15 2 0xB0 0x00 0x15 2 0xB6 0x03 0x15 2 0xBA 0x87 0x15 2 0xBD 0x78
				0x15 2 0xBF 0x15 0x15 2 0xC0 0x12 0x15 2 0xC2 0x0C 0x15 2 0xC3 0x02
				0x15 2 0xC4 0x0C 0x15 2 0xC5 0x02 0x15 2 0xB0 0x06 0x15 2 0xC0 0xA5
				0x15 2 0xD5 0x20 0x15 2 0xC0 0x00
				0x15 2 0xB0 0x02 /* page2 */
				0x15 2 0xC0 0x00 0x15 2 0xC1 0x02 0x15 2 0xC2 0x06 0x15 2 0xC3 0x16
				0x15 2 0xC4 0x0E 0x15 2 0xC5 0x18 0x15 2 0xC6 0x26 0x15 2 0xC7 0x32
				0x15 2 0xC8 0x3F 0x15 2 0xC9 0x3F 0x15 2 0xCA 0x3F 0x15 2 0xCB 0x3F
				0x15 2 0xCC 0x3D 0x15 2 0xCD 0x2F 0x15 2 0xCE 0x2F 0x15 2 0xCF 0x2F
				0x15 2 0xD0 0x07 0x15 2 0xD2 0x00 0x15 2 0xD3 0x02 0x15 2 0xD4 0x06
				0x15 2 0xD5 0x12 0x15 2 0xD6 0x0A 0x15 2 0xD7 0x14 0x15 2 0xD8 0x22
				0x15 2 0xD9 0x2E 0x15 2 0xDA 0x3D 0x15 2 0xDB 0x3F 0x15 2 0xDC 0x3F
				0x15 2 0xDD 0x3F 0x15 2 0xDE 0x3D 0x15 2 0xDF 0x2F 0x15 2 0xE0 0x2F
				0x15 2 0xE1 0x2F 0x15 2 0xE2 0x07
				0x15 2 0xB0 0x07 /* page7 */
				0x15 2 0xB1 0x00 0x15 2 0xB2 0x19 0x15 2 0xB3 0x31 0x15 2 0xB4 0x5A
				0x15 2 0xB5 0x7C 0x15 2 0xB6 0x9C 0x15 2 0xB7 0xD3 0x15 2 0xB8 0x0E
				0x15 2 0xB9 0x7D 0x15 2 0xBA 0xE0 0x15 2 0xBB 0x7A 0x15 2 0xBC 0xE6
				0x15 2 0xBD 0xE9 0x15 2 0xBE 0x41 0x15 2 0xBF 0x91 0x15 2 0xC0 0xB0
				0x15 2 0xC1 0xCF 0x15 2 0xC2 0xDC 0x15 2 0xC3 0xE9 0x15 2 0xC4 0xEF
				0x15 2 0xC5 0xF5 0x15 2 0xC6 0xFA 0x15 2 0xC7 0xFB 0x15 2 0xC8 0xFC
				0x15 2 0xC9 0x00 0x15 2 0xCA 0x01 0x15 2 0xCB 0x5A 0x15 2 0xCC 0xBF
				0x15 2 0xCD 0xFF 0x15 2 0xCE 0xFF
				0x15 2 0xB0 0x08 /* page8 */
				0x15 2 0xB1 0x00 0x15 2 0xB2 0x19 0x15 2 0xB3 0x31 0x15 2 0xB4 0x5A
				0x15 2 0xB5 0x7C 0x15 2 0xB6 0x9C 0x15 2 0xB7 0xD3 0x15 2 0xB8 0x0E
				0x15 2 0xB9 0x7D 0x15 2 0xBA 0xE0 0x15 2 0xBB 0x7A 0x15 2 0xBC 0xE6
				0x15 2 0xBD 0xE9 0x15 2 0xBE 0x41 0x15 2 0xBF 0x91 0x15 2 0xC0 0xB0
				0x15 2 0xC1 0xCF 0x15 2 0xC2 0xDC 0x15 2 0xC3 0xE9 0x15 2 0xC4 0xEF
				0x15 2 0xC5 0xF5 0x15 2 0xC6 0xFA 0x15 2 0xC7 0xFB 0x15 2 0xC8 0xFC
				0x15 2 0xC9 0x00 0x15 2 0xCA 0x01 0x15 2 0xCB 0x5A 0x15 2 0xCC 0xBF
				0x15 2 0xCD 0xFF 0x15 2 0xCE 0xFF
				0x15 2 0xB0 0x09 /* page9 */
				0x15 2 0xB1 0x00 0x15 2 0xB2 0x19 0x15 2 0xB3 0x31 0x15 2 0xB4 0x5A
				0x15 2 0xB5 0x7C 0x15 2 0xB6 0x9C 0x15 2 0xB7 0xD3 0x15 2 0xB8 0x0E
				0x15 2 0xB9 0x7D 0x15 2 0xBA 0xE0 0x15 2 0xBB 0x7A 0x15 2 0xBC 0xE6
				0x15 2 0xBD 0xE9 0x15 2 0xBE 0x41 0x15 2 0xBF 0x91 0x15 2 0xC0 0xB0
				0x15 2 0xC1 0xCF 0x15 2 0xC2 0xDC 0x15 2 0xC3 0xE9 0x15 2 0xC4 0xEF
				0x15 2 0xC5 0xF5 0x15 2 0xC6 0xFA 0x15 2 0xC7 0xFB 0x15 2 0xC8 0xFC
				0x15 2 0xC9 0x00 0x15 2 0xCA 0x01 0x15 2 0xCB 0x5A 0x15 2 0xCC 0xBF
				0x15 2 0xCD 0xFF 0x15 2 0xCE 0xFF
				0x15 2 0xB0 0x0A /* page10 */
				0x15 2 0xB1 0x00 0x15 2 0xB2 0x19 0x15 2 0xB3 0x31 0x15 2 0xB4 0x5A
				0x15 2 0xB5 0x7C 0x15 2 0xB6 0x9C 0x15 2 0xB7 0xD3 0x15 2 0xB8 0x0E
				0x15 2 0xB9 0x7D 0x15 2 0xBA 0xE0 0x15 2 0xBB 0x7A 0x15 2 0xBC 0xE6
				0x15 2 0xBD 0xE9 0x15 2 0xBE 0x41 0x15 2 0xBF 0x91 0x15 2 0xC0 0xB0
				0x15 2 0xC1 0xCF 0x15 2 0xC2 0xDC 0x15 2 0xC3 0xE9 0x15 2 0xC4 0xEF
				0x15 2 0xC5 0xF5 0x15 2 0xC6 0xFA 0x15 2 0xC7 0xFC 0x15 2 0xC8 0xFC
				0x15 2 0xC9 0x00 0x15 2 0xCA 0x01 0x15 2 0xCB 0x5A 0x15 2 0xCC 0xBF
				0x15 2 0xCD 0xFF 0x15 2 0xCE 0xFF
				0x15 2 0xB0 0x0B /* page11 */
				0x15 2 0xB1 0x00 0x15 2 0xB2 0x19 0x15 2 0xB3 0x31 0x15 2 0xB4 0x5A
				0x15 2 0xB5 0x7C 0x15 2 0xB6 0x9C 0x15 2 0xB7 0xD3 0x15 2 0xB8 0x0E
				0x15 2 0xB9 0x7D 0x15 2 0xBA 0xE0 0x15 2 0xBB 0x7A 0x15 2 0xBC 0xE6
				0x15 2 0xBD 0xE9 0x15 2 0xBE 0x41 0x15 2 0xBF 0x91 0x15 2 0xC0 0xB0
				0x15 2 0xC1 0xCF 0x15 2 0xC2 0xDC 0x15 2 0xC3 0xE9 0x15 2 0xC4 0xEF
				0x15 2 0xC5 0xF5 0x15 2 0xC6 0xFA 0x15 2 0xC7 0xFC 0x15 2 0xC8 0xFC
				0x15 2 0xC9 0x00 0x15 2 0xCA 0x01 0x15 2 0xCB 0x5A 0x15 2 0xCC 0xBF
				0x15 2 0xCD 0xFF 0x15 2 0xCE 0xFF
				0x15 2 0xB0 0x0C /* page12 */
				0x15 2 0xB1 0x00 0x15 2 0xB2 0x19 0x15 2 0xB3 0x31 0x15 2 0xB4 0x5A
				0x15 2 0xB5 0x7C 0x15 2 0xB6 0x9C 0x15 2 0xB7 0xD3 0x15 2 0xB8 0x0E
				0x15 2 0xB9 0x7D 0x15 2 0xBA 0xE0 0x15 2 0xBB 0x7A 0x15 2 0xBC 0xE6
				0x15 2 0xBD 0xE9 0x15 2 0xBE 0x41 0x15 2 0xBF 0x91 0x15 2 0xC0 0xB0
				0x15 2 0xC1 0xCF 0x15 2 0xC2 0xDC 0x15 2 0xC3 0xE9 0x15 2 0xC4 0xEF
				0x15 2 0xC5 0xF5 0x15 2 0xC6 0xFA 0x15 2 0xC7 0xFC 0x15 2 0xC8 0xFC
				0x15 2 0xC9 0x00 0x15 2 0xCA 0x01 0x15 2 0xCB 0x5A 0x15 2 0xCC 0xBF
				0x15 2 0xCD 0xFF 0x15 2 0xCE 0xFF
				0xfd 1 10
				0x05 1 0x11
				0xfd 1 100
				0x05 1 0x29
				0xfd 1 50
				0xff 0>; /*ending*/
			dsi_init_off = <
				0x05 1 0x28
				0xfd 1 10
				0x05 1 0x10
				0xff 0>;
			extern_init = <0xff>; /*0xff for invalid*/

			/* power step: type, index, value, delay(ms) */
			power_on_step = <
				0 0 1 100
				0 1 0 10
				0 1 1 20
				2 0 0 0
				0xff 0 0 0>; /*ending*/
			power_off_step = <
				2 0 0 50
				0 1 0 10
				0 0 0 100
				0xff 0 0 0>; /*ending*/
			backlight_index = <0x1>;
		};

		dsi_1 {
			model_name = "LX70WSK40164-V0";
			interface = "mipi";
			/*h_active, v_active, h_period, v_period, color_bit, width, height*/
			basic_setting = <600 1024 940 1058 8 90 153>;
			/*hs_width, hs_bp, hs_pol, vs_width, vs_bp, vs_pol*/
			lcd_timing = <60 140 0 4 14 0>;
			/* fr_adj_type(0=clk, 1=htotal, 2=vtotal), clk_ss_level, 1, pixel_clk */
			clk_attr = <2 0 1 60>;
			/* <lane, bit_rate, /, mode_init(0=video,1=cmd), mode_disp(0=video,1=cmd)*/
			/* video_mode(0=sync_pulse,1=sync_event,2=burst), clk_hs, />*/
			mipi_attr = <4 360 0 1 0 2 1 0>;
			/* dsi_init: data_type, num, data... */
			dsi_init_on = <
				0x39 4 0xB9 0xF1 0x12 0x87
				0x39 28 0xBA 0x33 0x81 0x05 0xF9 0x0E 0x0E 0x20 0x00 0x00 0x00 0x00
					0x00 0x00 0x00 0x44 0x25 0x00 0x91 0x0A 0x00 0x00 0x01 0x4F
					0x01 0x00 0x00 0x37
				0x39 4 0xB2 0x00 0x15 0x78
				0x39 11 0xB3 0x28 0x28 0x28 0x28 0x03 0xFF 0x00 0x00 0x00 0x00
				0x15 2 0xB4 0xA0
				0x39 3 0xB5 0x09 0x09
				0x39 3 0xB6 0x78 0x78
				0x39 3 0xB8 0x26 0x22
				0x15 2 0xBC 0x46
				0x39 6 0xBF 0x02 0x11 0x00 0x80 0x04
				0x39 10 0xC0 0x73 0x73 0x50 0x50 0x00 0x00 0x08 0x73 0x00
				0x39 18 0xC1 0x54 0x00 0x32 0x32 0x77 0xF1 0x3C 0x3C 0x7E 0x7E 0xCF
					0xCF 0x11 0x11 0x00 0x00 0x32
				0x39 13 0xC7 0xB8 0x00 0x0A 0x00 0x00 0x00 0x00 0x80 0xED 0xC7 0x00
					0xA5
				0x39 5 0xC8 0x10 0x40 0x1E 0x03
				0x39 2 0xCC 0x0B
				0x39 35 0xE0 0x00 0x02 0x03 0x23 0x38 0x3F 0x2D 0x27 0x04 0x08 0x0A
					0x0F 0x11 0x0E 0x11 0x12 0x18 0x00 0x02 0x03 0x23 0x38 0x3F
					0x2D 0x27 0x04 0x08 0x0A 0x0F 0x11 0x0E 0x11 0x12 0x18
				0x39 8 0xE1 0x11 0x11 0x91 0x00 0x00 0x00 0x00
				0x39 15 0xE3 0x07 0x07 0x0B 0x0B 0x03 0x0B 0x00 0x00 0x00 0x00 0xFF
					0x04 0xC0 0x10
				0x39 64 0xE9 0xC8 0x10 0x03 0x04 0x0A 0x80 0x81 0x12 0x31 0x23 0x4F
					0x81 0x80 0x81 0x37 0x08 0x00 0x04 0x08 0x00 0x00 0x00 0x00
					0x04 0x08 0x00 0x00 0x00 0x88 0x94 0xF8 0x13 0x57 0x18 0x88
					0x88 0x88 0x88 0x88 0x88 0x94 0xF8 0x02 0x46 0x08 0x88 0x88
					0x88 0x88 0x88 0x00 0x00 0x00 0x00 0x00 0x80 0x81 0x30 0x00
					0x00 0x00 0x00 0x00
				0x39 64 0xEA 0x01 0x10 0x01 0x02 0x03 0x00 0x00 0x00 0x00 0x00 0x00
					0x00 0x88 0x88 0x88 0x88 0x88 0x88 0x88 0x88 0x88 0x88 0x88
					0x88 0x88 0x88 0x88 0x88 0x88 0x88 0x88 0x88 0x88 0x88 0x23
					0x00 0x00 0x00 0xB8 0x00 0x00 0x00 0x00 0x00 0x00 0x00 0x00
					0x00 0x00 0x00 0x04 0x0D 0x12 0x30 0x30 0x80 0x81 0x50 0x80
					0x81 0x00 0x00 0x00
				0x39 4 0xEF 0xFF 0xFF 0x01
				0x05 1 0x11
				0xfd 1 250
				0x05 1 0x29
				0xfd 1 50
				0xff 0>; /*ending*/
			dsi_init_off = <
				0x05 1 0x28
				0xfd 1 10 /*delay(ms)*/
				0x05 1 0x10
				0xfd 1 10 /*delay(ms)*/
				0xff 0>; /*ending*/
			extern_init = <0x01>; /*0xff for invalid*/

			/* power step: type, index, value, delay(ms) */
			power_on_step = <
				0 0 1 10 /* LCD_VCC */
				0 2 1 0  /* GPIOY_5: BL_EN, IO_VDD */
				0 1 0 10 /* !need gpio pull high RST */
				0 1 1 15 /* LCD_RST */
				2 0 0 0
				0 4 1 0 /* GPIOY_15: BL_PWM */
				0xff 0 0 0>; /*ending*/
			power_off_step = <
				0 4 0 40
				2 0 0 50
				0 2 0 5
				0 1 0 5
				0 0 0 0
				0xff 0 0 0>; /*ending*/
			backlight_index = <0xff>;
		};
		dsi_2 {
			model_name = "LQ101R1SX01A";
			interface = "mipi";
			/*h_active, v_active, h_period, v_period, color_bit, width, height*/
			basic_setting = <2560 1600 2720 1646 8 228 148>;
			/*hs_width, hs_bp, hs_pol, vs_width, vs_bp, vs_pol*/
			lcd_timing = <32 80 0 6 36 0>;
			/* fr_adj_type(0=clk, 1=htotal, 2=vtotal), clk_ss_level, 1, pixel_clk */
			clk_attr = <2 0 1 60>;
			/* <lane, bit_rate, /, mode_init(0=video,1=cmd), mode_disp(0=video,1=cmd)*/
			/* video_mode(0=sync_pulse,1=sync_event,2=burst), clk_hs, />*/
			mipi_attr = <4 850 0x21 1 0 2 1 0>;
			/* dsi_init: data_type, num, data... */
			dsi_init_on = <
				/* 0x29 3 0x10 0x00 0x00 */
				0xf5 1 0x3 /*to port A&B*/
				0x05 1 0x11
				0xfd 1 40
				0xf5 1 0x1 /*to port A*/
				0x05 1 0x29
				0xfd 1 20
				0xff 0>; /*ending*/
			dsi_init_off = <
				0x05 1 0x28
				0xfd 1 50 /*delay(ms)*/
				0x05 1 0x10
				0xfd 1 200 /*delay(ms)*/
				0xff 0>; /*ending*/
			extern_init = <0xff>; /*0xff for invalid*/

			/* power step: type, index, value, delay(ms) */
			power_on_step = <
				0 0 1 300 /* LCD_VCC */
				2 0 0 0
				0xff 0 0 0>; /*ending*/
			power_off_step = <
				2 0 0 50
				0 0 0 200
				0xff 0 0 0>; /*ending*/
			backlight_index = <0xff>;
		};

		dsi_detect{
			model_name = "dsi_panel_detect";
			interface = "mipi";

			//<H_active, V_active, H_period, V_period, lcd_bits, width, height>
			basic_setting = <640 480 800 525 8 40 30>;
			//<HSync, HS_backporch, HS_pol, VSync, VS_backporch, VS_pol>
			lcd_timing = <96 40 0 2 25 0>;
			//<fr_adj_type clk_ss clk_auto_generate PixelClk>
			clk_attr = <0xff 0 1 25175000>;
			//<lane_num bit_rate \ mode_init mode_display video_mode clk_always_hs \>
			mipi_attr = <4 200 0 1 0 2 1 0>;

			//<stored2env \ \ \>
			dsi_detect_attr = <1 0 0 0>;
			/* dsi_init: data_type, num, data... */
			det0_init_table = <
				0x39 4 0xff 0x98 0x81 0x01
				0x06 1 0x00 0x06 1 0x01 0x06 1 0x02
				0xff 0>;
			det0_match_seq = <3 0x98 0x81 0x5c>;
			det0_type = "mipi_2";

			det1_match_seq = <8 0xff 0xff 0xff 0xff 0xff 0xff 0xff 0xff>;
			det1_type = "mipi_1";

			fallback_type = "mipi_0";

			/* power step: type, index, value, delay(ms) */
			power_on_step = <
				0 0 1 10 /*vcc en*/
				0 1 1 1 /*rst high*/
				0 3 1 30 /*3v3 high*/
				0 1 0 10 /*rst low*/
				0 1 1 20 /*rst high*/
				2 0 0 0
				0 0 0 1
				0 1 0 1 /*rst low*/
				0 3 0 1 /*3v3 low*/
				0xff 0 0 0>; /*ending*/
			power_off_step = <0xff 0 0 0>; /*ending*/
			backlight_index = <0xff>;
		};

		ports {
			port {
				#address-cells = <1>;
				#size-cells = <0>;
				lcd0_to_drm: endpoint@0 {
					reg = <0>;
					remote-endpoint = <0>;
				};
			};
		};
	};

	lcd1:lcd1 {
		compatible = "amlogic, lcd-a9";
		status = "disabled";
		index = <1>;
		mode = "tablet";
		fr_auto_policy = <1>; /* 0=disable, 1=60/50hz, 2=60/50/48hz */
		key_valid = <0>;
		reg = <0x0 0xfe01e000 0x0 0x400   /* mipi_dsi0-A host */
			0x0 0xfe01c000 0x0 0x200   /* mipi_dsi0-A phy */
			0x0 0xfe072000 0x0 0x400   /* mipi_dsi0-B host */
			0x0 0xfe018000 0x0 0x200   /* mipi_dsi0-B phy */
			0x0 0xfe016000 0x0 0x3e4
			0x0 0xfe004000 0x0 0x070>;  /* vx1_lvds_ctrl */
		interrupts = <0 197 1>, <0 194 1>, <0 208 1>;
		interrupt-names = "vsync","vsync2","vbyone";
		config_check_glb = <1>;
		display_timing_req_min = <1  /*alert_level: 0:disable, 1:warning, 2:fatal error*/
			45   /*hsw+hbp*/
			0    /*hfp, 0 for no need*/
			20   /*vsw+vbp*/
			15>; /*vfp*/
		//lcd_cpu-gpios = <&gpio GPIOY_4 GPIO_ACTIVE_LOW>;
		//lcd_cpu_gpio_names = "GPIOY_4";
		lvds_0{
			model_name = "1080p-vfreq";
			interface = "lvds"; /*lcd_interface(lvds, vbyone)*/
			basic_setting = <
				1920 1080 /*h_active, v_active*/
				2200 1125 /*h_period, v_period*/
				8      /*lcd_bits */
				16 9>; /*screen_widht, screen_height*/
			range_setting = <
				2132 2650  /*h_period_min,max*/
				1120 1480  /*v_period_min,max*/
				120000000 160000000>; /*pclk_min,max*/
			lcd_timing = <
				44 148 0  /*hs_width, hs_bp, hs_pol*/
				5  20 0>; /*vs_width, vs_bp, vs_pol*/
			clk_attr = <
				2 /*fr_adj_type: 0=clk, 1=htotal, 2=vtotal, 3=auto, 4=hdmi */
				0 /*clk_ss: [0:7]:level, [8:11]:freq, [12:15]: mode*/
				1 /*clk_auto_generate*/
				0>; /*pixel_clk(unit in Hz)*/
			lvds_attr = <
				1  /*lvds_repack*/
				1  /*dual_port*/
				0  /*pn_swap*/
				0  /*port_swap*/
				0>; /*lane_reverse*/
			phy_attr=<0x3 0>; /*vswing_level, preem_level*/
			hw_filter=<0 0>;  /* filter_time, filter_cnt*/

			/* power step: type, index, value, delay(ms) */
			power_on_step = <
				2 0 0 0   /*signal enable*/
				0xff 0 0 0>; /*ending*/
			power_off_step = <
				2 0 0 10  /*signal disable*/
				0xff 0 0 0>; /*ending*/
			backlight_index = <0xff>;
		};
		lvds_1{
			model_name = "lvds-1port";
			interface = "lvds"; /*lcd_interface(lvds, vbyone)*/
			basic_setting = <
				1024 600 /*h_active, v_active*/
				1364 638 /*h_period, v_period*/
				8      /*lcd_bits */
				16 9>; /*screen_widht, screen_height*/
			range_setting = <
				1300 1400  /*h_period_min,max*/
				629  660  /*v_period_min,max*/
				50000000 60000000>; /*pclk_min,max*/
			lcd_timing = <
				20 160 0  /*hs_width, hs_bp, hs_pol*/
				3  23  0>; /*vs_width, vs_bp, vs_pol*/
			clk_attr = <
				2 /*fr_adj_type: 0=clk, 1=htotal, 2=vtotal, 3=auto, 4=hdmi */
				0 /*clk_ss: [0:7]:level, [8:11]:freq, [12:15]: mode*/
				1 /*clk_auto_generate*/
				0>; /*pixel_clk(unit in Hz)*/
			lvds_attr = <
				1  /*lvds_repack*/
				0  /*dual_port*/
				0  /*pn_swap*/
				0  /*port_swap*/
				0>; /*lane_reverse*/
			phy_attr=<0x3 0>; /*vswing_level, preem_level*/
			hw_filter=<0 0>;  /* filter_time, filter_cnt*/

			/* power step: type, index, value, delay(ms) */
			power_on_step = <
				0 0 1 200  /*panel power on*/
				2 0 0 10  /*signal enable*/
				0xff 0 0 0>; /*ending*/
			power_off_step = <
				2 0 0 10  /*signal disable*/
				0xff 0 0 0>; /*ending*/
			backlight_index = <0xff>;
		};
		vbyone_0{
			model_name = "public_2region";
			interface = "vbyone"; /*lcd_interface(lvds, vbyone)*/
			basic_setting = <
				3840 2160 /*h_active, v_active*/
				4400 2250 /*h_period, v_period*/
				10     /*lcd_bits */
				1210 680>; /*screen_widht, screen_height*/
			range_setting = <
				4370 4800 /*h_period_min, max*/
				2246 2760 /*v_period_min, max*/
				480000000 624000000>; /*pclk_min, max*/
			lcd_timing = <
				33 477 0  /*hs_width, hs_bp, hs_pol*/
				6  65 0>; /*vs_width, vs_bp, vs_pol*/
			clk_attr = <
				2 /*fr_adj_type: 0=clk, 1=htotal, 2=vtotal, 3=auto, 4=hdmi */
				0 /*clk_ss: [0:7]:level, [8:11]:freq, [12:15]: mode*/
				1 /*clk_auto_generate*/
				0>; /*pixel_clk(unit in Hz)*/
			vbyone_attr = <
				8 /*lane_count*/
				2 /*region_num*/
				4 /*byte_mode*/
				4>; /*color_fmt*/
			vbyone_intr_enable = <
				1 /*vbyone_intr_enable */
				3>; /*vbyone_vsync_intr_enable*/
			phy_attr=<0x8 0xf>; /* vswing_level, preem_level */
			hw_filter=<0 0>;  /* filter_time, filter_cnt*/

			/* power step: type, index, value, delay(ms) */
			power_on_step = <
				0 0 1 200  /*panel power on*/
				2 0 0 10  /*signal enable*/
				0xff 0 0 0>; /*ending*/
			power_off_step = <
				2 0 0 10 /*signal disable*/
				0 0 0 500  /*panel power off*/
				0xff 0 0 0>; /*ending*/
			backlight_index = <0>;
		};
		vbyone_1{
			model_name = "public_1region";
			interface = "vbyone"; /*lcd_interface(lvds, vbyone)*/
			basic_setting = <
				3840 2160 /*h_active, v_active*/
				4400 2250 /*h_period, v_period*/
				10     /*lcd_bits*/
				1270 721>; /*screen_widht, screen_height*/
			range_setting = <
				4370 4800 /*h_period_min, max*/
				2246 2790 /*v_period_min, max*/
				552000000 632000000>; /*pclk_min,max*/
			lcd_timing = <
				33 477 0   /*hs_width, hs_bp, hs_pol*/
				6  65  0>; /*vs_width, vs_bp, vs_pol*/
			clk_attr = <
				2 /*fr_adj_type: 0=clk, 1=htotal, 2=vtotal, 3=auto, 4=hdmi */
				0 /*clk_ss: [0:7]:level, [8:11]:freq, [12:15]: mode*/
				1 /*clk_auto_generate*/
				0>; /*pixel_clk(unit in Hz)*/
			vbyone_attr = <
				8 /*lane_count*/
				1 /*region_num*/
				4 /*byte_mode*/
				4>; /*color_fmt*/
			vbyone_intr_enable = <
				1   /*vbyone_intr_enable*/
				3>; /*vbyone_vsync_intr_enable*/
			phy_attr=<0x8 0xf>; /* vswing_level, preem_level */
			hw_filter=<0 0>;  /* filter_time, filter_cnt*/

			/* power step: type, index, value, delay(ms) */
			power_on_step = <
				0 0 1 200  /*panel power on*/
				2 0 0 10 /*signal enable*/
				0xff 0 0 0>; /*ending*/
			power_off_step = <
				2 0 0 10  /*signal disable*/
				0 0 0 500  /*panel power off*/
				0xff 0 0 0>; /*ending*/
			backlight_index = <0>;
		};
		vbyone_2{
			model_name = "vbyone_1region_hdmi";
			interface = "vbyone"; /*lcd_interface(lvds, vbyone)*/
			basic_setting = <
				3840 2160 /*h_active, v_active*/
				4400 2250 /*h_period, v_period*/
				10     /*lcd_bits */
				1210 680>; /*screen_widht, screen_height*/
			range_setting = <
				4370 4800 /*h_period_min, max*/
				2246 2760 /*v_period_min, max*/
				480000000 624000000>; /*pclk_min, max*/
			lcd_timing = <
				33 477 0  /*hs_width, hs_bp, hs_pol*/
				6  65 0>; /*vs_width, vs_bp, vs_pol*/
			clk_attr = <
				4 /*fr_adj_type: 0=clk, 1=htotal, 2=vtotal, 3=auto, 4=hdmi */
				0 /*clk_ss: [0:7]:level, [8:11]:freq, [12:15]: mode*/
				1 /*clk_auto_generate*/
				0>; /*pixel_clk(unit in Hz)*/
			vbyone_attr = <
				8 /*lane_count*/
				1 /*region_num*/
				4 /*byte_mode*/
				4>; /*color_fmt*/
			vbyone_intr_enable = <
				1 /*vbyone_intr_enable */
				3>; /*vbyone_vsync_intr_enable*/
			phy_attr=<0x8 0xf>; /* vswing_level, preem_level */
			hw_filter=<0 0>;  /* filter_time, filter_cnt*/
			//vlock_attr: <vlock_en vlock_mode pll_m limit line_limit>
			vlock_attr = <0 4 0 3>;
			/* power step: type, index, value, delay(ms) */
			power_on_step = <
				0 0 1 20  /*panel power on*/
				2 0 0 0  /*signal enable*/
				0xff 0 0 0>; /*ending*/
			power_off_step = <
				2 0 0 20 /*signal disable*/
				0 0 0 100 /*panel power off*/
				0xff 0 0 0>; /*ending*/
			backlight_index = <0xff>;
		};
		vbyone_3{
			model_name = "vbyone_2region_hdmi";
			interface = "vbyone"; /*lcd_interface(lvds, vbyone)*/
			basic_setting = <
				3840 2160 /*h_active, v_active*/
				4400 2250 /*h_period, v_period*/
				10     /*lcd_bits */
				1210 680>; /*screen_widht, screen_height*/
			range_setting = <
				4370 4800 /*h_period_min, max*/
				2246 2760 /*v_period_min, max*/
				480000000 624000000>; /*pclk_min, max*/
			lcd_timing = <
				33 477 0  /*hs_width, hs_bp, hs_pol*/
				6  65 0>; /*vs_width, vs_bp, vs_pol*/
			clk_attr = <
				4 /*fr_adj_type: 0=clk, 1=htotal, 2=vtotal, 3=auto, 4=hdmi */
				0 /*clk_ss: [0:7]:level, [8:11]:freq, [12:15]: mode*/
				1 /*clk_auto_generate*/
				0>; /*pixel_clk(unit in Hz)*/
			vbyone_attr = <
				8 /*lane_count*/
				2 /*region_num*/
				4 /*byte_mode*/
				4>; /*color_fmt*/
			vbyone_intr_enable = <
				1 /*vbyone_intr_enable */
				3>; /*vbyone_vsync_intr_enable*/
			phy_attr=<0x8 0xf>; /* vswing_level, preem_level */
			hw_filter=<0 0>;  /* filter_time, filter_cnt*/
			//vlock_attr: <vlock_en vlock_mode pll_m limit line_limit>
			vlock_attr = <0 4 0 3>;
			/* power step: type, index, value, delay(ms) */
			power_on_step = <
				0 0 1 20  /*panel power on*/
				2 0 0 0  /*signal enable*/
				0xff 0 0 0>; /*ending*/
			power_off_step = <
				2 0 0 20 /*signal disable*/
				0 0 0 100 /*panel power off*/
				0xff 0 0 0>; /*ending*/
			backlight_index = <0xff>;
		};

		edp_0{
			model_name = "edp_1080p60";
			interface = "edp"; /*lcd_interface(lvds, vbyone)*/
			basic_setting = <
				1920 1080 /*h_active, v_active*/
				2200 1125 /*h_period, v_period*/
				8      /*lcd_bits*/
				344 193>; /*screen_widht, screen_height*/
			lcd_timing = <
				44 148 0   /*hs_width, hs_bp, hs_pol*/
				5  20  0>; /*vs_width, vs_bp, vs_pol*/
			clk_attr = <
				0xff /*fr_adj_type: 0=clk, 1=htotal, 2=vtotal, 3=auto, 4=hdmi */
				0 /*clk_ss_level */
				1 /*clk_auto_generate*/
				0>; /*pixel_clk(unit in Hz)*/
			edp_attr = <
				2 /*max_lane_count: 0:auto, 1, 2, 4*/
				0xa /*max_link_rate: 0:auto, 0x6:1.62G, 0xa:2.7G*/
				0 /*training_mode: 0:auto, 1:fast, 2:full*/
				0 /*edid_en, auto timing by edid*/
				0 /*reserved */
				0 /*reserved */
				0 /*reserved */
				0 /*reserved */
				0>; /*reserved*/
			phy_attr=<0x5 1>; /*vswing_level, preem_level*/

			/* power step: type, index, value, delay(ms) */
			power_on_step = <
				0 0 1 50  /*panel power on*/
				2 0 0 0   /*signal enable*/
				0xff 0 0 0>; /*ending*/
			power_off_step = <
				2 0 0 10  /*signal disable*/
				0 0 0 200  /*panel power on*/
				0xff 0 0 0>; /*ending*/
			backlight_index = <0x0>;
		};
		edp_1{
			model_name = "edp_edid";
			interface = "edp"; /*lcd_interface(lvds, vbyone)*/
			basic_setting = <
				2560 1440 /*h_active, v_active*/
				2640 1481 /*h_period, v_period*/
				8      /*lcd_bits*/
				344 193>; /*screen_widht, screen_height*/
			lcd_timing = <
				32 40 0   /*hs_width, hs_bp, hs_pol*/
				8  6  0>; /*vs_width, vs_bp, vs_pol*/
			clk_attr = <
				2 /*fr_adj_type: 0=clk, 1=htotal, 2=vtotal, 3=auto, 4=hdmi */
				0 /*clk_ss_level */
				1 /*clk_auto_generate*/
				235000000>; /*pixel_clk(unit in Hz)*/
			edp_attr = <
				0 /*max_lane_count: 0:auto, 1, 2, 4*/
				0 /*max_link_rate: 0:auto, 0x6:1.62G, 0xa:2.7G*/
				0 /*training_mode: 0:auto, 1:fast, 2:full*/
				1 /*edid_en, auto timing by edid*/
				0 /*reserved */
				0 /*reserved */
				0 /*reserved */
				0 /*reserved */
				0>; /*reserved*/
			phy_attr=<0x5 1>; /*vswing_level, preem_level*/

			/* power step: type, index, value, delay(ms) */
			power_on_step = <
				0 0 1 50  /*panel power on*/
				2 0 0 0   /*signal enable*/
				0xff 0 0 0>; /*ending*/
			power_off_step = <
				2 0 0 10  /*signal disable*/
				0 0 0 200  /*panel power on*/
				0xff 0 0 0>; /*ending*/
			backlight_index = <0x0>;
		};

		mipi_0{
			model_name = "TL070WSH27";
			interface = "mipi";
			basic_setting = <1024 600 /*h_active, v_active*/
				1250 630 /*h_period, v_period*/
				8 /*lcd_bits*/
				154 86>; /*screen_widht, screen_height*/
			range_setting = <
				1250 1250 /*h_period min, max*/
				630 788 /*v_period min, max*/
				47250000 47250000>; /*pclk_min, max*/
			lcd_timing = <80 100 0 /*hs_width, hs_bp, hs_pol*/
				5 20 0>; /*vs_width, vs_bp, vs_pol*/
			clk_attr = <2 /*fr_adj_type(0=clk, 1=htotal, 2=vtotal)*/
				0 /*clk_ss_level */
				1 /*clk_auto_generate*/
				47250000>; /*pixel_clk(unit in Hz)*/
			mipi_attr = <4 /*lane_num*/
				300 /*bit_rate_max(MHz)*/
				0 /*unused*/
				1 /*operation_mode_init(0=video, 1=command)*/
				0 /*operation_mode_display(0=video, 1=command)*/
				2 /*video_mode_type: 0=sync_pulse,1=sync_event,2=burst)*/
				1 /*clk_always_hs(0=disable,1=enable)*/
				0>; /*unused*/

			/* dsi_init: data_type, num, data... */
			dsi_init_on = <0x05 1 0x11
					0xfd 1 20     /*delay(ms)*/
					0x05 1 0x29
					0xfd 1 20     /*delay(ms)*/
					0xff 0>; /*ending*/
			dsi_init_off = <0x05 1 0x28
					0xfd 1 10     /*delay(ms)*/
					0x05 1 0x10
					0xfd 1 10     /*delay(ms)*/
					0xff 0>; /*ending*/
			extern_init = <0xff>; /*0xff for invalid*/

			/* power step: type, index, value, delay(ms) */
			power_on_step = <
				0 0 1 100
				0 1 0 10
				0 1 1 20
				2 0 0 0
				0xff 0 0 0>; /*ending*/
			power_off_step = <
				2 0 0 50
				0 1 0 10
				0 0 0 100
				0xff 0 0 0>; /*ending*/
			backlight_index = <0x1>;
		};
		mipi_1{
			model_name = "SLT_720P";
			interface = "mipi";
			basic_setting = <1280 720 /*h_active, v_active*/
				1590 750 /*h_period, v_period*/
				8 /*lcd_bits*/
				154 86>; /*screen_widht, screen_height*/
			lcd_timing = <40 60 0 /*hs_width,hs_bp,hs_pol*/
				5 20 0>; /*vs_width,vs_bp,vs_pol*/
			clk_attr = <0 /*fr_adj_type(0=clock,1=htotal,2=vtotal)*/
				0 /*clk_ss: [0:7]:level, [8:11]:freq, [12:15]: mode*/
				1 /*clk_auto_generate*/
				74250000>; /*pixel_clk(unit in Hz)*/
			mipi_attr = <4 /*lane_num*/
				550 /*bit_rate_max(MHz)*/
				0 /*unused*/
				1 /*operation_mode_init(0=video, 1=command)*/
				0 /*operation_mode_display(0=video, 1=command)*/
				0 /*video_mode_type: 0=sync_pulse,1=sync_event,2=burst)*/
				1 /*clk_always_hs(0=disable,1=enable)*/
				0>; /*unused*/
			/* dsi_init: data_type, num, data... */
			dsi_init_on = <
				0x05 1 0x11
				0xff 200
				0x05 1 0x29
				0xff 20
				0xff 0xff>; /* ending flag */
			dsi_init_off = <
				0x05 1 0x28
				0xff 10
				0x05 1 0x10
				0xff 10
				0xff 0xff>; /* ending flag */
				/* extern_init: 0xff for invalid */
			extern_init = <0xff>;
				/* power step: type,index,value,delay(ms) */
			power_on_step = <
					3 7 0 100
					2 0 0 0
					0xff 0 0 0>;
			power_off_step = <
					2 0 0 0
					0xff 0 0 0>;
			backlight_index = <0xff>;
		};

		dsi_0{
			model_name = "AML08012001920-02";
			interface = "mipi";
			/*h_active, v_active, h_period, v_period, color_bit, width, height*/
			basic_setting = <1200 1920 1380 1960 8 135 216>;
			/*hs_width, hs_bp, hs_pol, vs_width, vs_bp, vs_pol*/
			lcd_timing = <50 80 0 4 20 0>;
			clk_attr = <2 0 1 164000000>;
			/* <lane, bit_rate, /, mode_init(0=video,1=cmd), mode_disp(0=video,1=cmd)*/
			/* video_mode(0=sync_pulse,1=sync_event,2=burst), clk_hs, />*/
			mipi_attr = <4 995 0 1 0 2 1 0>;
			/* dsi_init: data_type, num, data... */
			dsi_init_on = <
				0xfd 1 150
				0x05 1 0x10
				0xfd 1 10
				0x15 2 0xB0 0x05 0x15 2 0xB3 0x52 0x15 2 0xB0 0x01 0x15 2 0xC8 0x00
				0x15 2 0xC9 0x00 0x15 2 0xCC 0x26 0x15 2 0xCD 0x26 0x15 2 0xDC 0x00
				0x15 2 0xDD 0x00 0x15 2 0xE0 0x26 0x15 2 0xE1 0x26 0x15 2 0xB0 0x03
				0x15 2 0xC3 0x2A 0x15 2 0xE7 0x2A 0x15 2 0xC5 0x2A 0x15 2 0xDE 0x2A
				0x15 2 0xB0 0x00 0x15 2 0xB6 0x03 0x15 2 0xBA 0x87 0x15 2 0xBD 0x78
				0x15 2 0xBF 0x15 0x15 2 0xC0 0x12 0x15 2 0xC2 0x0C 0x15 2 0xC3 0x02
				0x15 2 0xC4 0x0C 0x15 2 0xC5 0x02 0x15 2 0xB0 0x06 0x15 2 0xC0 0xA5
				0x15 2 0xD5 0x20 0x15 2 0xC0 0x00
				0x15 2 0xB0 0x02 /* page2 */
				0x15 2 0xC0 0x00 0x15 2 0xC1 0x02 0x15 2 0xC2 0x06 0x15 2 0xC3 0x16
				0x15 2 0xC4 0x0E 0x15 2 0xC5 0x18 0x15 2 0xC6 0x26 0x15 2 0xC7 0x32
				0x15 2 0xC8 0x3F 0x15 2 0xC9 0x3F 0x15 2 0xCA 0x3F 0x15 2 0xCB 0x3F
				0x15 2 0xCC 0x3D 0x15 2 0xCD 0x2F 0x15 2 0xCE 0x2F 0x15 2 0xCF 0x2F
				0x15 2 0xD0 0x07 0x15 2 0xD2 0x00 0x15 2 0xD3 0x02 0x15 2 0xD4 0x06
				0x15 2 0xD5 0x12 0x15 2 0xD6 0x0A 0x15 2 0xD7 0x14 0x15 2 0xD8 0x22
				0x15 2 0xD9 0x2E 0x15 2 0xDA 0x3D 0x15 2 0xDB 0x3F 0x15 2 0xDC 0x3F
				0x15 2 0xDD 0x3F 0x15 2 0xDE 0x3D 0x15 2 0xDF 0x2F 0x15 2 0xE0 0x2F
				0x15 2 0xE1 0x2F 0x15 2 0xE2 0x07
				0x15 2 0xB0 0x07 /* page7 */
				0x15 2 0xB1 0x00 0x15 2 0xB2 0x19 0x15 2 0xB3 0x31 0x15 2 0xB4 0x5A
				0x15 2 0xB5 0x7C 0x15 2 0xB6 0x9C 0x15 2 0xB7 0xD3 0x15 2 0xB8 0x0E
				0x15 2 0xB9 0x7D 0x15 2 0xBA 0xE0 0x15 2 0xBB 0x7A 0x15 2 0xBC 0xE6
				0x15 2 0xBD 0xE9 0x15 2 0xBE 0x41 0x15 2 0xBF 0x91 0x15 2 0xC0 0xB0
				0x15 2 0xC1 0xCF 0x15 2 0xC2 0xDC 0x15 2 0xC3 0xE9 0x15 2 0xC4 0xEF
				0x15 2 0xC5 0xF5 0x15 2 0xC6 0xFA 0x15 2 0xC7 0xFB 0x15 2 0xC8 0xFC
				0x15 2 0xC9 0x00 0x15 2 0xCA 0x01 0x15 2 0xCB 0x5A 0x15 2 0xCC 0xBF
				0x15 2 0xCD 0xFF 0x15 2 0xCE 0xFF
				0x15 2 0xB0 0x08 /* page8 */
				0x15 2 0xB1 0x00 0x15 2 0xB2 0x19 0x15 2 0xB3 0x31 0x15 2 0xB4 0x5A
				0x15 2 0xB5 0x7C 0x15 2 0xB6 0x9C 0x15 2 0xB7 0xD3 0x15 2 0xB8 0x0E
				0x15 2 0xB9 0x7D 0x15 2 0xBA 0xE0 0x15 2 0xBB 0x7A 0x15 2 0xBC 0xE6
				0x15 2 0xBD 0xE9 0x15 2 0xBE 0x41 0x15 2 0xBF 0x91 0x15 2 0xC0 0xB0
				0x15 2 0xC1 0xCF 0x15 2 0xC2 0xDC 0x15 2 0xC3 0xE9 0x15 2 0xC4 0xEF
				0x15 2 0xC5 0xF5 0x15 2 0xC6 0xFA 0x15 2 0xC7 0xFB 0x15 2 0xC8 0xFC
				0x15 2 0xC9 0x00 0x15 2 0xCA 0x01 0x15 2 0xCB 0x5A 0x15 2 0xCC 0xBF
				0x15 2 0xCD 0xFF 0x15 2 0xCE 0xFF
				0x15 2 0xB0 0x09 /* page9 */
				0x15 2 0xB1 0x00 0x15 2 0xB2 0x19 0x15 2 0xB3 0x31 0x15 2 0xB4 0x5A
				0x15 2 0xB5 0x7C 0x15 2 0xB6 0x9C 0x15 2 0xB7 0xD3 0x15 2 0xB8 0x0E
				0x15 2 0xB9 0x7D 0x15 2 0xBA 0xE0 0x15 2 0xBB 0x7A 0x15 2 0xBC 0xE6
				0x15 2 0xBD 0xE9 0x15 2 0xBE 0x41 0x15 2 0xBF 0x91 0x15 2 0xC0 0xB0
				0x15 2 0xC1 0xCF 0x15 2 0xC2 0xDC 0x15 2 0xC3 0xE9 0x15 2 0xC4 0xEF
				0x15 2 0xC5 0xF5 0x15 2 0xC6 0xFA 0x15 2 0xC7 0xFB 0x15 2 0xC8 0xFC
				0x15 2 0xC9 0x00 0x15 2 0xCA 0x01 0x15 2 0xCB 0x5A 0x15 2 0xCC 0xBF
				0x15 2 0xCD 0xFF 0x15 2 0xCE 0xFF
				0x15 2 0xB0 0x0A /* page10 */
				0x15 2 0xB1 0x00 0x15 2 0xB2 0x19 0x15 2 0xB3 0x31 0x15 2 0xB4 0x5A
				0x15 2 0xB5 0x7C 0x15 2 0xB6 0x9C 0x15 2 0xB7 0xD3 0x15 2 0xB8 0x0E
				0x15 2 0xB9 0x7D 0x15 2 0xBA 0xE0 0x15 2 0xBB 0x7A 0x15 2 0xBC 0xE6
				0x15 2 0xBD 0xE9 0x15 2 0xBE 0x41 0x15 2 0xBF 0x91 0x15 2 0xC0 0xB0
				0x15 2 0xC1 0xCF 0x15 2 0xC2 0xDC 0x15 2 0xC3 0xE9 0x15 2 0xC4 0xEF
				0x15 2 0xC5 0xF5 0x15 2 0xC6 0xFA 0x15 2 0xC7 0xFC 0x15 2 0xC8 0xFC
				0x15 2 0xC9 0x00 0x15 2 0xCA 0x01 0x15 2 0xCB 0x5A 0x15 2 0xCC 0xBF
				0x15 2 0xCD 0xFF 0x15 2 0xCE 0xFF
				0x15 2 0xB0 0x0B /* page11 */
				0x15 2 0xB1 0x00 0x15 2 0xB2 0x19 0x15 2 0xB3 0x31 0x15 2 0xB4 0x5A
				0x15 2 0xB5 0x7C 0x15 2 0xB6 0x9C 0x15 2 0xB7 0xD3 0x15 2 0xB8 0x0E
				0x15 2 0xB9 0x7D 0x15 2 0xBA 0xE0 0x15 2 0xBB 0x7A 0x15 2 0xBC 0xE6
				0x15 2 0xBD 0xE9 0x15 2 0xBE 0x41 0x15 2 0xBF 0x91 0x15 2 0xC0 0xB0
				0x15 2 0xC1 0xCF 0x15 2 0xC2 0xDC 0x15 2 0xC3 0xE9 0x15 2 0xC4 0xEF
				0x15 2 0xC5 0xF5 0x15 2 0xC6 0xFA 0x15 2 0xC7 0xFC 0x15 2 0xC8 0xFC
				0x15 2 0xC9 0x00 0x15 2 0xCA 0x01 0x15 2 0xCB 0x5A 0x15 2 0xCC 0xBF
				0x15 2 0xCD 0xFF 0x15 2 0xCE 0xFF
				0x15 2 0xB0 0x0C /* page12 */
				0x15 2 0xB1 0x00 0x15 2 0xB2 0x19 0x15 2 0xB3 0x31 0x15 2 0xB4 0x5A
				0x15 2 0xB5 0x7C 0x15 2 0xB6 0x9C 0x15 2 0xB7 0xD3 0x15 2 0xB8 0x0E
				0x15 2 0xB9 0x7D 0x15 2 0xBA 0xE0 0x15 2 0xBB 0x7A 0x15 2 0xBC 0xE6
				0x15 2 0xBD 0xE9 0x15 2 0xBE 0x41 0x15 2 0xBF 0x91 0x15 2 0xC0 0xB0
				0x15 2 0xC1 0xCF 0x15 2 0xC2 0xDC 0x15 2 0xC3 0xE9 0x15 2 0xC4 0xEF
				0x15 2 0xC5 0xF5 0x15 2 0xC6 0xFA 0x15 2 0xC7 0xFC 0x15 2 0xC8 0xFC
				0x15 2 0xC9 0x00 0x15 2 0xCA 0x01 0x15 2 0xCB 0x5A 0x15 2 0xCC 0xBF
				0x15 2 0xCD 0xFF 0x15 2 0xCE 0xFF
				0xfd 1 10
				0x05 1 0x11
				0xfd 1 100
				0x05 1 0x29
				0xfd 1 50
				0xff 0>; /*ending*/
			dsi_init_off = <
				0x05 1 0x28
				0xfd 1 10
				0x05 1 0x10
				0xff 0>;
			extern_init = <0xff>; /*0xff for invalid*/

			/* power step: type, index, value, delay(ms) */
			power_on_step = <
				0 0 1 100
				0 1 0 10
				0 1 1 20
				2 0 0 0
				0xff 0 0 0>; /*ending*/
			power_off_step = <
				2 0 0 50
				0 1 0 10
				0 0 0 100
				0xff 0 0 0>; /*ending*/
			backlight_index = <0x1>;
		};

		ports {
			port {
				#address-cells = <1>;
				#size-cells = <0>;
				lcd1_to_drm: endpoint@0 {
					reg = <0>;
					remote-endpoint = <0>;
				};
			};
		};
	};

}; /* end of / */
